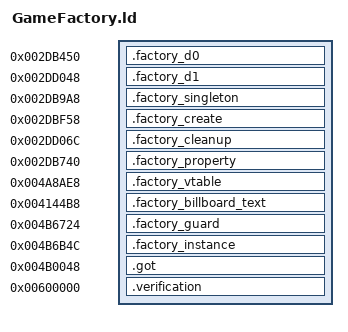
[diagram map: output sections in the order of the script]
OUTPUT_FORMAT("elf32-littlearm")
OUTPUT_ARCH(arm)
ENTRY(_ZN12CGameFactory11getInstanceEv)
INCLUDE build/matches/game-factory/retail-symbols.ld
_ZdlPv = 0x001c42b0;
_Znwj = 0x001c4814;
__cxa_guard_acquire = 0x001c4958;
__cxa_guard_release = 0x001c46c4;
__aeabi_atexit = 0x001c494c;
strstr = 0x001c446c;
strchr = 0x001c48e0;
strlen = 0x001c48bc;
memcpy = 0x001c4190;
atoi = 0x001c4880;
__stack_chk_fail = 0x001c42e0;
SECTIONS {
    .factory_d0 0x002db450 : { *game-factory.o(.gnu.linkonce.t._ZN12CGameFactoryD0Ev) }
    .factory_d1 0x002dd048 : { *game-factory.o(.gnu.linkonce.t._ZN12CGameFactoryD1Ev .gnu.linkonce.t._ZN12CGameFactoryD2Ev) }
    .factory_singleton 0x002db9a8 : { *game-factory.o(.gnu.linkonce.t._ZN12CGameFactory11getInstanceEv .text._ZN12CGameFactory11getInstanceEv) }
    .factory_create 0x002dbf58 : { *game-factory.o(.gnu.linkonce.t._ZN12CGameFactory10createNodeERKN3irr7collada16CColladaDatabaseEPNS1_5SNodeE) }
    .factory_cleanup 0x002dd06c : { *game-factory.o(.text.__tcf_0) }
    .factory_property 0x002db740 : { *game-factory.o(.text._ZN9GS3DStuff11getPropertyEPKvPKcPc) }
    .factory_vtable 0x004a8ae8 : { *game-factory.o(.gnu.linkonce.d.rel.ro._ZTV12CGameFactory) }
    .factory_billboard_text 0x004144b8 : { *game-factory.o(.rodata.game_factory_billboard) }
    .factory_guard 0x004b6724 (NOLOAD) : { *game-factory.o(.gnu.linkonce.b._ZGVZN12CGameFactory11getInstanceEvE2gf) }
    .factory_instance 0x004b6b4c (NOLOAD) : { *game-factory.o(.gnu.linkonce.b._ZZN12CGameFactory11getInstanceEvE2gf) }
    .got 0x004b0048 : { *(.got.plt) . = 0x360; *(.got) }
    .verification 0x00600000 : { *retail-got.o(.text) }
}
